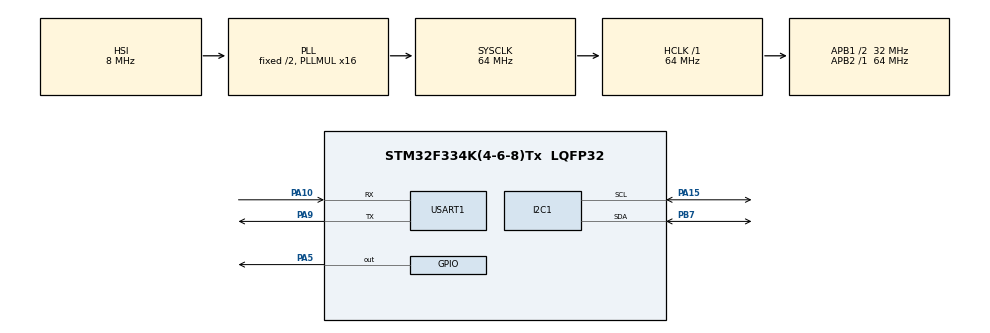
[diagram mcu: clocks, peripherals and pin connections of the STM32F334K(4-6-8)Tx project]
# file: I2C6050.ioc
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I2C1.Speed=100
I2C1.Timing=0x2000090E
Mcu.Family=STM32F3
Mcu.Name=STM32F334K(4-6-8)Tx
Mcu.Package=LQFP32
NVIC.I2C1_ER_IRQn=true\:0\:0\:false
NVIC.I2C1_EV_IRQn=true\:0\:0\:false
NVIC.PriorityGroup=NVIC_PRIORITYGROUP_4
PA10.Mode=Asynchronous
PA10.Signal=USART1_RX
PA15.Mode=I2C
PA15.Signal=I2C1_SCL
PA5.Signal=GPIO_Output
PA9.Mode=Asynchronous
PA9.Signal=USART1_TX
PB7.Mode=I2C
PB7.Signal=I2C1_SDA
ProjectManager.TargetToolchain=SW4STM32
RCC.AHBFreq_Value=64000000
RCC.APB1CLKDivider=RCC_HCLK_DIV2
RCC.APB1Freq_Value=32000000
RCC.APB1TimFreq_Value=64000000
RCC.APB2Freq_Value=64000000
RCC.APB2TimFreq_Value=64000000
RCC.CortexFreq_Value=64000000
RCC.HCLKFreq_Value=64000000
RCC.HSE_VALUE=8000000
RCC.HSI_VALUE=8000000
RCC.PLLMUL=RCC_PLL_MUL16
RCC.SYSCLKFreq_VALUE=64000000
RCC.SYSCLKSourceVirtual=RCC_SYSCLKSOURCE_PLLCLK
USART1.WordLength=UART_WORDLENGTH_8B
board=I2C6050

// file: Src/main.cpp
/**
  ******************************************************************************
  * File Name          : main.c
  * Description        : Main program body
  ******************************************************************************
  *
  * COPYRIGHT(c) 2016 STMicroelectronics
  *
  * Redistribution and use in source and binary forms, with or without modification,
  * are permitted provided that the following conditions are met:
  *   1. Redistributions of source code must retain the above copyright notice,
  *      this list of conditions and the following disclaimer.
  *   2. Redistributions in binary form must reproduce the above copyright notice,
  *      this list of conditions and the following disclaimer in the documentation
  *      and/or other materials provided with the distribution.
  *   3. Neither the name of STMicroelectronics nor the names of its contributors
  *      may be used to endorse or promote products derived from this software
  *      without specific prior written permission.
  *
  * THIS SOFTWARE IS PROVIDED BY THE COPYRIGHT HOLDERS AND CONTRIBUTORS "AS IS"
  * AND ANY EXPRESS OR IMPLIED WARRANTIES, INCLUDING, BUT NOT LIMITED TO, THE
  * IMPLIED WARRANTIES OF MERCHANTABILITY AND FITNESS FOR A PARTICULAR PURPOSE ARE
  * DISCLAIMED. IN NO EVENT SHALL THE COPYRIGHT HOLDER OR CONTRIBUTORS BE LIABLE
  * FOR ANY DIRECT, INDIRECT, INCIDENTAL, SPECIAL, EXEMPLARY, OR CONSEQUENTIAL
  * DAMAGES (INCLUDING, BUT NOT LIMITED TO, PROCUREMENT OF SUBSTITUTE GOODS OR
  * SERVICES; LOSS OF USE, DATA, OR PROFITS; OR BUSINESS INTERRUPTION) HOWEVER
  * CAUSED AND ON ANY THEORY OF LIABILITY, WHETHER IN CONTRACT, STRICT LIABILITY,
  * OR TORT (INCLUDING NEGLIGENCE OR OTHERWISE) ARISING IN ANY WAY OUT OF THE USE
  * OF THIS SOFTWARE, EVEN IF ADVISED OF THE POSSIBILITY OF SUCH DAMAGE.
  *
  ******************************************************************************
  */
#include "stm32f3xx_hal.h"
#include "i2c.h"
#include "usart.h"
#include "gpio.h"

/* USER CODE BEGIN Includes */
#include "T6050.h"
/* USER CODE END Includes */

/* USER CODE BEGIN PV */
/* Private variables ---------------------------------------------------------*/

/* USER CODE END PV */

void SystemClock_Config(void);

/* USER CODE BEGIN PFP */
/* Private function prototypes -----------------------------------------------*/

/* USER CODE END PFP */

int main(void)
{

  /* USER CODE BEGIN 1 */
	DWT->CYCCNT = 0;
  /* Enable counter */
	DWT->CTRL &= ~0x00000001;
	DWT->CTRL |= 0x00000001;
  /* USER CODE END 1 */

  /* MCU Configuration----------------------------------------------------------*/

  /* Reset of all peripherals, Initializes the Flash interface and the Systick. */
  HAL_Init();

  /* Configure the system clock */
  SystemClock_Config();

  /* Initialize all configured peripherals */
  MX_GPIO_Init();
  MX_I2C1_Init();
  MX_USART1_UART_Init();

  /* USER CODE BEGIN 2 */
	setup();
  /* USER CODE END 2 */

  /* Infinite loop */
  while (1)
  {

  /* USER CODE BEGIN 3 */
	  loop();
  }
  /* USER CODE END 3 */

}

/** System Clock Configuration
*/
void SystemClock_Config(void)
{

  RCC_OscInitTypeDef RCC_OscInitStruct;
  RCC_ClkInitTypeDef RCC_ClkInitStruct;
  RCC_PeriphCLKInitTypeDef PeriphClkInit;

  RCC_OscInitStruct.OscillatorType = RCC_OSCILLATORTYPE_HSI;
  RCC_OscInitStruct.HSIState = RCC_HSI_ON;
  RCC_OscInitStruct.HSICalibrationValue = 16;
  RCC_OscInitStruct.PLL.PLLState = RCC_PLL_ON;
  RCC_OscInitStruct.PLL.PLLSource = RCC_PLLSOURCE_HSI;
  RCC_OscInitStruct.PLL.PLLMUL = RCC_PLL_MUL16;
  HAL_RCC_OscConfig(&RCC_OscInitStruct);

  RCC_ClkInitStruct.ClockType = RCC_CLOCKTYPE_SYSCLK|RCC_CLOCKTYPE_PCLK1;
  RCC_ClkInitStruct.SYSCLKSource = RCC_SYSCLKSOURCE_PLLCLK;
  RCC_ClkInitStruct.AHBCLKDivider = RCC_SYSCLK_DIV1;
  RCC_ClkInitStruct.APB1CLKDivider = RCC_HCLK_DIV2;
  RCC_ClkInitStruct.APB2CLKDivider = RCC_HCLK_DIV1;
  HAL_RCC_ClockConfig(&RCC_ClkInitStruct, FLASH_LATENCY_2);

  PeriphClkInit.PeriphClockSelection = RCC_PERIPHCLK_USART1|RCC_PERIPHCLK_I2C1;
  PeriphClkInit.Usart1ClockSelection = RCC_USART1CLKSOURCE_PCLK1;
  PeriphClkInit.I2c1ClockSelection = RCC_I2C1CLKSOURCE_HSI;
  HAL_RCCEx_PeriphCLKConfig(&PeriphClkInit);

  HAL_SYSTICK_Config(HAL_RCC_GetHCLKFreq()/1000);

  HAL_SYSTICK_CLKSourceConfig(SYSTICK_CLKSOURCE_HCLK);

  /* SysTick_IRQn interrupt configuration */
  HAL_NVIC_SetPriority(SysTick_IRQn, 0, 0);
}

/************************ (C) COPYRIGHT STMicroelectronics *****END OF FILE****/
